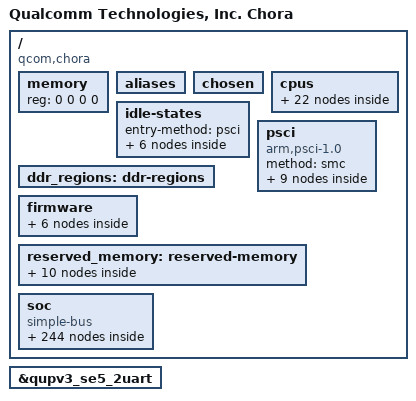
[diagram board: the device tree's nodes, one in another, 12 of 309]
// SPDX-License-Identifier: BSD-3-Clause
/*
 * Copyright (c) Qualcomm Technologies, Inc. and/or its subsidiaries.
 */

#include <dt-bindings/arm/msm/qti-smmu-proxy-dt-ids.h>
#include <dt-bindings/clock/qcom,chora-camcc.h>
#include <dt-bindings/clock/qcom,chora-dispcc.h>
#include <dt-bindings/clock/qcom,chora-gcc.h>
#include <dt-bindings/clock/qcom,chora-gpucc.h>
#include <dt-bindings/clock/qcom,chora-tcsrcc.h>
#include <dt-bindings/clock/qcom,chora-videocc.h>
#include <dt-bindings/clock/qcom,rpmh.h>
#include <dt-bindings/interrupt-controller/arm-gic.h>
#include <dt-bindings/soc/qcom,ipcc.h>
#include <dt-bindings/mailbox/qcom-ipcc-chora.h>
#include <dt-bindings/gpio/gpio.h>
#include <dt-bindings/soc/qcom,rpmh-rsc.h>
#include <dt-bindings/regulator/qcom,rpmh-regulator-levels.h>
#include <dt-bindings/interconnect/qcom,icc.h>
#include <dt-bindings/interconnect/qcom,chora.h>
#include <dt-bindings/spmi/spmi.h>
#include <dt-bindings/dma/qcom-gpi.h>

/ {
	model = "Qualcomm Technologies, Inc. Chora";
	compatible = "qcom,chora";
	qcom,msm-id = <724 0x10000>;
	interrupt-parent = <&intc>;

	#address-cells = <2>;
	#size-cells = <2>;
	memory { device_type = "memory"; reg = <0 0 0 0>; };

	aliases: aliases {
		serial0 = &qupv3_se5_2uart;
		ufshc1 = &ufshc_mem; /* Embedded UFS Slot */
		mmc1 = &sdhc_2; /* SDC2 SD card slot */
		hsuart0 = &qupv3_se11_4uart;
		i2c0 = &qupv3_se0_i2c;
		i2c1 = &qupv3_se1_i2c;
		i2c2 = &qupv3_se2_i2c;
		i2c3 = &qupv3_se3_i2c;
		i2c4 = &qupv3_se4_i2c;
		i2c6 = &qupv3_se6_i2c;
		i2c7 = &qupv3_se7_i2c;
		i2c8 = &qupv3_se8_i2c;
		i2c9 = &qupv3_se9_i2c;
		i2c10 = &qupv3_se10_i2c;
		i2c12 = &qupv3_se12_i2c;
		i2c13 = &qupv3_se13_i2c;
		spi0 = &qupv3_se0_spi;
		spi1 = &qupv3_se1_spi;
		spi2 = &qupv3_se2_spi;
		spi3 = &qupv3_se3_spi;
		spi4 = &qupv3_se4_spi;
		spi6 = &qupv3_se6_spi;
		spi7 = &qupv3_se7_spi;
		spi8 = &qupv3_se8_spi;
		spi10 = &qupv3_se10_spi;
		spi12 = &qupv3_se12_spi;
		spi13 = &qupv3_se13_spi;
	};

	chosen: chosen {
		bootargs = "loglevel=6 log_buf_len=512K earlycon androidboot.usb.dwc3_msm=a600000.hsusb arm64.nosme arm64.nomte cpufreq.default_governor=performance no-steal-acc kpti=0 swiotlb=0 loop.max_part=7 irqaffinity=0-3 fw_devlink.strict=1 kasan=off ufshcd-core.use_mcq_mode=n rcupdate.rcu_expedited=1 rcu_nocbs=0-7 cgroup_disable=pressure cgroup.memory=nokmem,nosocket disable_dma32=on page_poison=on sysctl.kernel.sched_pelt_multiplier=4 android_arch_task_struct_size=512 printk.console_no_auto_verbose=1 sysctl.kernel.panic_on_rcu_stall=1 ftrace_dump_on_oops restrict_cma_redirect=false can.stats_timer=0 slub_debug=-";
		stdout-path = "serial0:115200n8";
	};

	cpus {
		#address-cells = <2>;
		#size-cells = <0>;

		CPU0: cpu@0 {
			device_type = "cpu";
			compatible = "qcom,kryo";
			reg = <0x0 0x0>;
			enable-method = "psci";
			cpu-idle-states = <&LITTLE_CPU_OFF &LITTLE_CPU_RAIL_OFF>;
			power-domains = <&CPU_PD0>;
			power-domain-names = "psci";
			next-level-cache = <&L2_0>;
			capacity-dmips-mhz = <1024>;
			dynamic-power-coefficient = <100>;
			#cooling-cells = <2>;
			qcom,freq-domain = <&cpufreq_hw 0>;

			L2_0: l2-cache {
				compatible = "arm,arch-cache";
				cache-level = <2>;
				next-level-cache = <&L3_0>;

				L3_0: l3-cache {
					compatible = "arm,arch-cache";
					cache-level = <3>;
				};
			};
		};

		CPU1: cpu@100 {
			device_type = "cpu";
			compatible = "qcom,kryo";
			reg = <0x0 0x100>;
			enable-method = "psci";
			cpu-idle-states = <&LITTLE_CPU_OFF &LITTLE_CPU_RAIL_OFF>;
			power-domains = <&CPU_PD1>;
			power-domain-names = "psci";
			next-level-cache = <&L2_0>;
			capacity-dmips-mhz = <1024>;
			dynamic-power-coefficient = <100>;
			#cooling-cells = <2>;
			qcom,freq-domain = <&cpufreq_hw 0>;
		};

		CPU2: cpu@200 {
			device_type = "cpu";
			compatible = "qcom,kryo";
			reg = <0x0 0x200>;
			enable-method = "psci";
			cpu-idle-states = <&LITTLE_CPU_OFF &LITTLE_CPU_RAIL_OFF>;
			power-domains = <&CPU_PD2>;
			power-domain-names = "psci";
			next-level-cache = <&L2_0>;
			capacity-dmips-mhz = <1024>;
			dynamic-power-coefficient = <100>;
			#cooling-cells = <2>;
			qcom,freq-domain = <&cpufreq_hw 0>;
		};

		CPU3: cpu@300 {
			device_type = "cpu";
			compatible = "qcom,kryo";
			reg = <0x0 0x300>;
			enable-method = "psci";
			cpu-idle-states = <&LITTLE_CPU_OFF &LITTLE_CPU_RAIL_OFF>;
			power-domains = <&CPU_PD3>;
			power-domain-names = "psci";
			next-level-cache = <&L2_0>;
			capacity-dmips-mhz = <1024>;
			dynamic-power-coefficient = <100>;
			#cooling-cells = <2>;
			qcom,freq-domain = <&cpufreq_hw 0>;
		};

		CPU4: cpu@400 {
			device_type = "cpu";
			compatible = "qcom,kryo";
			reg = <0x0 0x400>;
			enable-method = "psci";
			cpu-idle-states = <&BIG_CPU_OFF &BIG_CPU_RAIL_OFF>;
			power-domains = <&CPU_PD4>;
			power-domain-names = "psci";
			next-level-cache = <&L2_4>;
			capacity-dmips-mhz = <1864>;
			dynamic-power-coefficient = <471>;
			#cooling-cells = <2>;
			qcom,freq-domain = <&cpufreq_hw 1>;

			L2_4: l2-cache {
				compatible = "arm,arch-cache";
				cache-level = <2>;
				next-level-cache = <&L3_0>;
			};
		};

		CPU5: cpu@500 {
			device_type = "cpu";
			compatible = "qcom,kryo";
			reg = <0x0 0x500>;
			enable-method = "psci";
			cpu-idle-states = <&BIG_CPU_OFF &BIG_CPU_RAIL_OFF>;
			power-domains = <&CPU_PD5>;
			power-domain-names = "psci";
			next-level-cache = <&L2_4>;
			capacity-dmips-mhz = <1864>;
			dynamic-power-coefficient = <471>;
			#cooling-cells = <2>;
			qcom,freq-domain = <&cpufreq_hw 1>;
		};

		CPU6: cpu@600 {
			device_type = "cpu";
			compatible = "qcom,kryo";
			reg = <0x0 0x600>;
			enable-method = "psci";
			cpu-idle-states = <&BIG_CPU_OFF &BIG_CPU_RAIL_OFF>;
			power-domains = <&CPU_PD6>;
			power-domain-names = "psci";
			next-level-cache = <&L2_4>;
			capacity-dmips-mhz = <1864>;
			dynamic-power-coefficient = <471>;
			#cooling-cells = <2>;
			qcom,freq-domain = <&cpufreq_hw 1>;
		};

		CPU7: cpu@700 {
			device_type = "cpu";
			compatible = "qcom,kryo";
			reg = <0x0 0x700>;
			enable-method = "psci";
			cpu-idle-states = <&BIG_CPU_OFF &BIG_CPU_RAIL_OFF>;
			power-domains = <&CPU_PD7>;
			power-domain-names = "psci";
			next-level-cache = <&L2_4>;
			capacity-dmips-mhz = <1864>;
			dynamic-power-coefficient = <471>;
			#cooling-cells = <2>;
			qcom,freq-domain = <&cpufreq_hw 1>;
		};

		cpu-map {

			cluster0 {

				core0 {
					cpu = <&CPU0>;
				};

				core1 {
					cpu = <&CPU1>;
				};

				core2 {
					cpu = <&CPU2>;
				};

				core3 {
					cpu = <&CPU3>;
				};
			};

			cluster1 {

				core0 {
					cpu = <&CPU4>;
				};

				core1 {
					cpu = <&CPU5>;
				};

				core2 {
					cpu = <&CPU6>;
				};

				core3 {
					cpu = <&CPU7>;
				};
			};
		};
	};

	idle-states {
		entry-method = "psci";

		LITTLE_CPU_OFF: silver-c3 {  /* C3 */
			compatible = "arm,idle-state";
			idle-state-name = "pc";
			entry-latency-us = <203>;
			exit-latency-us = <358>;
			min-residency-us = <1774>;
			arm,psci-suspend-param = <0x40000003>;
			local-timer-stop;
		};

		LITTLE_CPU_RAIL_OFF: silver-c4 {  /* C4 */
			compatible = "arm,idle-state";
			idle-state-name = "rail-pc";
			entry-latency-us = <222>;
			exit-latency-us = <391>;
			min-residency-us = <4090>;
			arm,psci-suspend-param = <0x40000004>;
			local-timer-stop;
		};

		BIG_CPU_OFF: gold-c3 {  /* C3 */
			compatible = "arm,idle-state";
			idle-state-name = "pc";
			entry-latency-us = <330>;
			exit-latency-us = <890>;
			min-residency-us = <2207>;
			arm,psci-suspend-param = <0x40000003>;
			local-timer-stop;
		};

		BIG_CPU_RAIL_OFF: gold-c4 {  /* C4 */
			compatible = "arm,idle-state";
			idle-state-name = "rail-pc";
			entry-latency-us = <354>;
			exit-latency-us = <1344>;
			min-residency-us = <4791>;
			arm,psci-suspend-param = <0x40000004>;
			local-timer-stop;
		};

		CLUSTER_OFF: cluster-d4 { /* D4 */
			compatible = "domain-idle-state";
			idle-state-name = "l3-off";
			entry-latency-us = <690>;
			exit-latency-us = <1843>;
			min-residency-us = <5309>;
			arm,psci-suspend-param = <0x41000044>;
		};

		CX_RET: cx-ret { /* Cx Ret */
			compatible = "domain-idle-state";
			idle-state-name = "cx-ret";
			entry-latency-us = <528>;
			exit-latency-us = <2237>;
			min-residency-us = <8550>;
			arm,psci-suspend-param = <0x41003344>;
		};
	};

	psci: psci {
		compatible = "arm,psci-1.0";
		method = "smc";

		CPU_PD0: cpu-pd0 {
			#power-domain-cells = <0>;
			power-domains = <&CLUSTER_PD>;
		};

		CPU_PD1: cpu-pd1 {
			#power-domain-cells = <0>;
			power-domains = <&CLUSTER_PD>;
		};

		CPU_PD2: cpu-pd2 {
			#power-domain-cells = <0>;
			power-domains = <&CLUSTER_PD>;
		};

		CPU_PD3: cpu-pd3 {
			#power-domain-cells = <0>;
			power-domains = <&CLUSTER_PD>;
		};

		CPU_PD4: cpu-pd4 {
			#power-domain-cells = <0>;
			power-domains = <&CLUSTER_PD>;
		};

		CPU_PD5: cpu-pd5 {
			#power-domain-cells = <0>;
			power-domains = <&CLUSTER_PD>;
		};

		CPU_PD6: cpu-pd6 {
			#power-domain-cells = <0>;
			power-domains = <&CLUSTER_PD>;
		};

		CPU_PD7: cpu-pd7 {
			#power-domain-cells = <0>;
			power-domains = <&CLUSTER_PD>;
		};

		CLUSTER_PD: cluster-pd {
			#power-domain-cells = <0>;
			domain-idle-states = <&CLUSTER_OFF &CX_RET>;
		};
	};

	ddr_regions: ddr-regions { };

	firmware: firmware { };

	reserved_memory: reserved-memory { };

	soc: soc { };
};

&firmware {
	qcom_scm: qcom_scm {
		compatible = "qcom,scm";
		qcom,dload-mode = <&tcsr 0x19000>;
	};

	qcom,sps {
		compatible = "qcom,msm-sps-v1_7-4k";
		qcom,pipe-attr-ee;
	};

	qcom_smcinvoke {
		compatible = "qcom,smcinvoke";
	};

	qcom_mem_object {
		compatible = "qcom,mem-object";
	};

	qtee_shmbridge {
		compatible = "qcom,tee-shared-memory-bridge";
	};

	qcom,hdcp {
		compatible = "qcom,hdcp";
		qcom,use-smcinvoke = <1>;
	};

};

#include "chora-reserved-memory.dtsi"
#include "msm-arm-smmu-chora.dtsi"
#include "chora-dma-heaps.dtsi"

&reserved_memory {
	#address-cells = <2>;
	#size-cells = <2>;
	ranges;

	adsp_mem_heap: adsp_heap_region {
		compatible = "shared-dma-pool";
		alloc-ranges = <0x0 0x00000000 0x0 0xffffffff>;
		reusable;
		alignment = <0x0 0x400000>;
		size = <0x0 0xC00000>;
	};

	non_secure_display_memory: non_secure_display_region {
		compatible = "shared-dma-pool";
		reusable;
		alloc-ranges = <0x0 0x00000000 0x0 0xffffffff>;
		size = <0x0 0x5c00000>;
		alignment = <0x0 0x400000>;
	};

	/* global autoconfigured region for contiguous allocations */
	system_cma: linux,cma {
		compatible = "shared-dma-pool";
		alloc-ranges = <0x0 0x00000000 0x0 0xffffffff>;
		reusable;
		alignment = <0x0 0x400000>;
		size = <0x0 0x2400000>;
		linux,cma-default;
	};

	lcp_dare_pool: lcp_dare_region {
		compatible = "shared-dma-pool";
		reg = <0x8 0x80000000 0x0 0x6000000>;
		reusable;
		alignment = <0x0 0x400000>;
	};

	kinfo_mem: debug_kinfo_region {
		alloc-ranges = <0x0 0x00000000 0xffffffff 0xffffffff>;
		size = <0x0 0x1000>;
		no-map;
	};

	ramoops_mem: ramoops-region {
		alloc-ranges = <0x1 0x00000000 0xfffffffe 0xffffffff>;
		size = <0x0 0x200000>;
		no-map;
	};

	va_md_mem: va_md_mem_region {
		compatible = "shared-dma-pool";
		alloc-ranges = <0x0 0x00000000 0x0 0xffffffff>;
		reusable;
		size = <0 0x1000000>;
	};

	qseecom_mem: qseecom_region {
		compatible = "shared-dma-pool";
		alloc-ranges = <0x0 0x00000000 0x0 0xffffffff>;
		reusable;
		alignment = <0x0 0x400000>;
		size = <0x0 0x1400000>;
	};

	qseecom_ta_mem: qseecom_ta_region {
		compatible = "shared-dma-pool";
		alloc-ranges = <0x0 0x00000000 0x0 0xffffffff>;
		reusable;
		alignment = <0x0 0x400000>;
		size = <0x0 0x1400000>;
	};

	vm_comm_mem: vm_comm_mem_region {
		compatible = "shared-dma-pool";
		alloc-ranges = <0x0 0x00000000 0x0 0xffffffff>;
		reusable;
		alignment = <0x0 0x400000>;
		size = <0x0 0x800000>;
	};
};

&soc {
	#address-cells = <2>;
	#size-cells = <2>;
	ranges = <0 0 0 0 0x10 0>;
	compatible = "simple-bus";

	qcom,secure-buffer {
		compatible = "qcom,secure-buffer";
		qcom,vmid-cp-camera-preview-ro;
	};

	qcom,mem-buf {
		compatible = "qcom,mem-buf";
		qcom,mem-buf-capabilities = "supplier";
		qcom,vmid = <3>;
	};

	qcom,mem-buf-msgq {
		compatible = "qcom,mem-buf-msgq";
		qcom,msgq-names = "trusted_vm", "oem_vm";
	};

	qcom,test-large-dmabuf-tuivm {
		compatible = "qcom,gh-large-dmabuf-test";
		gunyah-label = <0x10d>;
		qcom,primary;
	};

	qcom,test-large-dmabuf-oemvm {
		compatible = "qcom,gh-large-dmabuf-test";
		gunyah-label = <0x10e>;
		qcom,primary;
	};

	msm_gpu: qcom,kgsl-3d0@3d00000 { };

	thermal_zones: thermal-zones {};

	intc: interrupt-controller@17200000 {
		compatible = "arm,gic-v3";
		#interrupt-cells = <3>;
		interrupt-controller;
		#redistributor-regions = <1>;
		redistributor-stride = <0x0 0x20000>;
		reg = <0x0 0x17200000 0x0 0x10000>,	/* GICD */
		      <0x0 0x17260000 0x0 0x100000>;	/* GICR * 8 */
		interrupts = <GIC_PPI 9 IRQ_TYPE_LEVEL_LOW>;

		#address-cells = <1>;
		#size-cells = <1>;
		ranges;
		gic_its: msi-controller@17240000 {
			compatible = "arm,gic-v3-its";
			msi-controller;
			#msi-cells = <1>;
			reg = <0x17240000 0x20000>;
		};
	};

	arch_timer: timer {
		compatible = "arm,armv8-timer";
		interrupts = <GIC_PPI 13 (GIC_CPU_MASK_SIMPLE(8) | IRQ_TYPE_LEVEL_LOW)>,
			     <GIC_PPI 14 (GIC_CPU_MASK_SIMPLE(8) | IRQ_TYPE_LEVEL_LOW)>,
			     <GIC_PPI 11 (GIC_CPU_MASK_SIMPLE(8) | IRQ_TYPE_LEVEL_LOW)>,
			     <GIC_PPI 10 (GIC_CPU_MASK_SIMPLE(8) | IRQ_TYPE_LEVEL_LOW)>;
		clock-frequency = <19200000>;
	};

	memtimer: timer@17420000 {
		compatible = "arm,armv7-timer-mem";
		reg = <0x0 0x17420000 0x0 0x1000>;
		clock-frequency = <19200000>;

		#address-cells = <1>;
		#size-cells = <1>;
		ranges;
		frame@17421000 {
			frame-number = <0>;
			interrupts = <GIC_SPI 8 IRQ_TYPE_LEVEL_HIGH>,
				     <GIC_SPI 6 IRQ_TYPE_LEVEL_HIGH>;
			reg = <0x17421000 0x1000>,
			      <0x17422000 0x1000>;
		};

		frame@17423000 {
			frame-number = <1>;
			interrupts = <GIC_SPI 9 IRQ_TYPE_LEVEL_HIGH>;
			reg = <0x17423000 0x1000>;
			status = "disabled";
		};

		frame@17425000 {
			frame-number = <2>;
			interrupts = <GIC_SPI 10 IRQ_TYPE_LEVEL_HIGH>;
			reg = <0x17425000 0x1000>;
			status = "disabled";
		};

		frame@17427000 {
			frame-number = <3>;
			interrupts = <GIC_SPI 11 IRQ_TYPE_LEVEL_HIGH>;
			reg = <0x17427000 0x1000>;
			status = "disabled";
		};

		frame@17429000 {
			frame-number = <4>;
			interrupts = <GIC_SPI 12 IRQ_TYPE_LEVEL_HIGH>;
			reg = <0x17429000 0x1000>;
			status = "disabled";
		};

		frame@1742b000 {
			frame-number = <5>;
			interrupts = <GIC_SPI 13 IRQ_TYPE_LEVEL_HIGH>;
			reg = <0x1742b000 0x1000>;
			status = "disabled";
		};

		frame@1742d000 {
			frame-number = <6>;
			interrupts = <GIC_SPI 14 IRQ_TYPE_LEVEL_HIGH>;
			reg = <0x1742d000 0x1000>;
			status = "disabled";
		};
	};

	apps_rsc: rsc@17a00000 {
		label = "apps_rsc";
		compatible = "qcom,rpmh-rsc";
		reg = <0x0 0x17a00000 0x0 0x10000>,
		      <0x0 0x17a10000 0x0 0x10000>,
		      <0x0 0x17a20000 0x0 0x10000>;
		reg-names = "drv-0", "drv-1", "drv-2";
		qcom,drv-count = <3>;
		interrupts = <GIC_SPI 3 IRQ_TYPE_LEVEL_HIGH>,
			     <GIC_SPI 4 IRQ_TYPE_LEVEL_HIGH>,
			     <GIC_SPI 5 IRQ_TYPE_LEVEL_HIGH>;
		power-domains = <&CLUSTER_PD>;

		apps_rsc_drv2: drv@2 {
			qcom,drv-id = <2>;
			qcom,tcs-offset = <0xd00>;
			qcom,tcs-distance = <0x2a0>;

			channel@0 {
				 qcom,tcs-config = <ACTIVE_TCS    3>,
						   <SLEEP_TCS     2>,
						   <WAKE_TCS      2>,
						   <CONTROL_TCS   0>,
						   <FAST_PATH_TCS 1>;
			};

			apps_bcm_voter: bcm_voter {
				compatible = "qcom,bcm-voter";
			};

			rpmhcc: clock-controller {
				compatible = "qcom,chora-rpmh-clk";
				#clock-cells = <1>;
			};

			dcvs_fp: qcom,dcvs-fp {
				compatible = "qcom,dcvs-fp";
				qcom,ddr-bcm-name = "MC4";
			};
		};
	};

	pdc: interrupt-controller@0xb220000 {
		compatible = "qcom,chora-pdc", "qcom,pdc";
		reg = <0x0 0xb220000 0x0 0x10000>,
		      <0x0 0x174000f0 0x0 0x64>;
		qcom,pdc-ranges = <0 480 40>, <40 140 11>, <51 527 47>,
				  <98 609 31>, <129 63 1>, <130 716 12>,
				  <142 251 5>;
		#interrupt-cells = <2>;
		interrupt-parent = <&intc>;
		interrupt-controller;
	};

	disp_rsc: rsc@af20000 {
		label = "disp_rsc";
		compatible = "qcom,rpmh-rsc";
		reg = <0x0 0xaf20000 0x0 0x10000>;
		reg-names = "drv-0";
		qcom,drv-count = <1>;
		interrupts = <GIC_SPI 129 IRQ_TYPE_LEVEL_HIGH>;
		clocks = <&dispcc DISP_CC_MDSS_RSCC_AHB_CLK>;

		disp_rsc_drv0: drv@0 {
			qcom,tcs-offset = <0x1c00>;
			qcom,drv-id = <0>;
			channel@0 {
				qcom,tcs-config = <ACTIVE_TCS    0>,
						  <SLEEP_TCS     1>,
						  <WAKE_TCS      1>,
						  <CONTROL_TCS   0>,
						  <FAST_PATH_TCS 0>;
			};

			disp_bcm_voter: bcm_voter {
				compatible = "qcom,bcm-voter";
				qcom,tcs-wait = <QCOM_ICC_TAG_AMC>;
			};
		};
	};

	cluster-device {
		compatible = "qcom,lpm-cluster-dev";
		power-domains = <&CLUSTER_PD>;
	};

	gic-interrupt-router {
		compatible = "qcom,gic-intr-routing";
		/* keep few silver cores in class0 only to avoid wakeup of gold cores */
		qcom,gic-class0-cpus = <&CPU0 &CPU1 &CPU2 &CPU3>;
		/* keep gold cores in class1 */
		qcom,gic-class1-cpus = <&CPU4 &CPU5 &CPU6 &CPU7>;
		qcom,gic-cpulist = <&CPU0 &CPU1 &CPU2 &CPU3 &CPU4 &CPU5 &CPU6 &CPU7>;
		qcom,gic-runtime-cpu-class-en;
	};

	wdog: qcom,wdt@17410000 {
		compatible = "qcom,msm-watchdog";
		reg = <0x0 0x17410000 0x0 0x1000>;
		reg-names = "wdt-base";
		interrupts = <GIC_SPI 0 IRQ_TYPE_LEVEL_HIGH>,
			     <GIC_SPI 1 IRQ_TYPE_LEVEL_HIGH>;
		qcom,bark-time = <11000>;
		qcom,pet-time = <9360>;
		qcom,ipi-ping;
		qcom,wakeup-enable;

		status = "ok";
	};

	kryo-erp {
		compatible = "arm,arm64-kryo-cpu-erp";
		interrupts = <GIC_PPI 0 IRQ_TYPE_LEVEL_HIGH>,
			<GIC_SPI 35 IRQ_TYPE_LEVEL_HIGH>;
		interrupt-names = "l1-l2-faultirq","l3-scu-faultirq";
	};

	qcom,chd {
		compatible = "qcom,core-hang-detect";
		label = "core";
		qcom,chd-percpu-info = <&CPU0 0x17800058 0x17800060>,
			<&CPU1 0x17810058 0x17810060>,
			<&CPU2 0x17820058 0x17820060>,
			<&CPU3 0x17830058 0x17830060>,
			<&CPU4 0x17840058 0x17840060>,
			<&CPU5 0x17850058 0x17850060>,
			<&CPU6 0x17860058 0x17860060>,
			<&CPU7 0x17870058 0x17870060>;
	};

	ipcc_mproc: qcom,ipcc@404000 {
		compatible = "qcom,ipcc";
		reg = <0x0 0x404000 0x0 0x1000>;
		interrupts = <GIC_SPI 256 IRQ_TYPE_LEVEL_HIGH>;
		interrupt-controller;
		#interrupt-cells = <3>;
		#mbox-cells = <2>;
	};

	spmi_bus: spmi0_bus: qcom,spmi@c42d000 {
		compatible = "qcom,spmi-pmic-arb";
		reg = <0x0 0xc42d000 0x0 0x4000>,
		      <0x0 0xc400000 0x0 0x3000>,
		      <0x0 0xc500000 0x0 0x400000>,
		      <0x0 0xc440000 0x0 0x80000>,
		      <0x0 0xc4c0000 0x0 0x10000>;
		reg-names = "cnfg", "core", "chnls", "obsrvr", "intr";
		interrupts-extended = <&pdc 1 IRQ_TYPE_LEVEL_HIGH>;
		interrupt-names = "periph_irq";
		interrupt-controller;
		#interrupt-cells = <4>;
		#address-cells = <2>;
		#size-cells = <0>;
		cell-index = <0>;
		qcom,channel = <0>;
		qcom,ee = <0>;
		qcom,bus-id = <0>;
	};

	aoss_qmp: power-controller@c300000 {
		compatible = "qcom,aoss-qmp";
		reg = <0x0 0xc300000 0x0 0x400>;
		interrupt-parent = <&ipcc_mproc>;
		interrupts = <IPCC_CLIENT_AOP
			      IPCC_MPROC_SIGNAL_GLINK_QMP
			      IRQ_TYPE_EDGE_RISING>;
		mboxes = <&ipcc_mproc IPCC_CLIENT_AOP
			  IPCC_MPROC_SIGNAL_GLINK_QMP>;

		#power-domain-cells = <1>;
		#clock-cells = <0>;
	};

	spmi_debug_bus_0: qcom,spmi-debug@10b14000 {
		compatible = "qcom,spmi-pmic-arb-debug";
		reg = <0x0 0x10b14000 0x0 0x60>,
		      <0x0 0x221c8780 0x0 0x4>;
		reg-names = "core", "fuse";
		clocks = <&aoss_qmp>;
		clock-names = "core_clk";
		qcom,fuse-enable-bit = <14>;
		#address-cells = <1>;
		#size-cells = <0>;
		depends-on-supply = <&spmi0_bus>;

		pmk8550@0 {
			compatible = "qcom,spmi-pmic";
			reg = <0 SPMI_USID>;
			#address-cells = <2>;
			#size-cells = <0>;
			qcom,can-sleep;
		};

		pmxr2230@1 {
			compatible = "qcom,spmi-pmic";
			reg = <1 SPMI_USID>;
			#address-cells = <2>;
			#size-cells = <0>;
			qcom,can-sleep;
		};

		pm8550vs@2 {
			compatible = "qcom,spmi-pmic";
			reg = <2 SPMI_USID>;
			#address-cells = <2>;
			#size-cells = <0>;
			qcom,can-sleep;
		};

		pmr735b@5 {
			compatible = "qcom,spmi-pmic";
			reg = <5 SPMI_USID>;
			#address-cells = <2>;
			#size-cells = <0>;
			qcom,can-sleep;
		};

		pm8010@c {
			compatible = "qcom,spmi-pmic";
			reg = <12 SPMI_USID>;
			#address-cells = <2>;
			#size-cells = <0>;
			qcom,can-sleep;
		};

		pm8010@d {
			compatible = "qcom,spmi-pmic";
			reg = <13 SPMI_USID>;
			#address-cells = <2>;
			#size-cells = <0>;
			qcom,can-sleep;
		};
	};

	qmp_tme: qcom,qmp-tme {
		compatible = "qcom,qmp-mbox";
		qcom,remote-pid = <14>;
		mboxes = <&ipcc_mproc IPCC_CLIENT_TME
			  IPCC_MPROC_SIGNAL_GLINK_QMP>;
		mbox-names = "tme_qmp";
		interrupt-parent = <&ipcc_mproc>;
		interrupts = <IPCC_CLIENT_TME
			      IPCC_MPROC_SIGNAL_GLINK_QMP
			      IRQ_TYPE_EDGE_RISING>;

		label = "tme";
		qcom,early-boot;
		priority = <0>;
		mbox-desc-offset = <0x0>;
		#mbox-cells = <1>;
	};

	qcom,smp2p-adsp {
		compatible = "qcom,smp2p";
		qcom,smem = <443>, <429>;
		interrupt-parent = <&ipcc_mproc>;
		interrupts = <IPCC_CLIENT_LPASS IPCC_MPROC_SIGNAL_SMP2P
			      IRQ_TYPE_EDGE_RISING>;
		mboxes = <&ipcc_mproc IPCC_CLIENT_LPASS
			  IPCC_MPROC_SIGNAL_SMP2P>;
		qcom,local-pid = <0>;
		qcom,remote-pid = <2>;

		adsp_smp2p_out: master-kernel {
			qcom,entry-name = "master-kernel";
			#qcom,smem-state-cells = <1>;
		};

		adsp_smp2p_in: slave-kernel {
			qcom,entry-name = "slave-kernel";
			interrupt-controller;
			#interrupt-cells = <2>;
		};

		sleepstate_smp2p_out: sleepstate-out {
			qcom,entry-name = "sleepstate";
			#qcom,smem-state-cells = <1>;
		};

		sleepstate_smp2p_in: qcom,sleepstate-in {
			qcom,entry-name = "sleepstate_see";
			interrupt-controller;
			#interrupt-cells = <2>;
		};

		smp2p_rdbg2_out: qcom,smp2p-rdbg2-out {
			qcom,entry-name = "rdbg";
			#qcom,smem-state-cells = <1>;
		};

		smp2p_rdbg2_in: qcom,smp2p-rdbg2-in {
			qcom,entry-name = "rdbg";
			interrupt-controller;
			#interrupt-cells = <2>;
		};
	};

	qcom,smp2p-modem {
		compatible = "qcom,smp2p";
		qcom,smem = <435>, <428>;
		interrupt-parent = <&ipcc_mproc>;
		interrupts = <IPCC_CLIENT_MPSS IPCC_MPROC_SIGNAL_SMP2P
			      IRQ_TYPE_EDGE_RISING>;
		mboxes = <&ipcc_mproc IPCC_CLIENT_MPSS IPCC_MPROC_SIGNAL_SMP2P>;
		qcom,local-pid = <0>;
		qcom,remote-pid = <1>;

		modem_smp2p_out: master-kernel {
			qcom,entry-name = "master-kernel";
			#qcom,smem-state-cells = <1>;
		};

		modem_smp2p_in: slave-kernel {
			qcom,entry-name = "slave-kernel";
			interrupt-controller;
			#interrupt-cells = <2>;
		};

		smp2p_ipa_1_out: qcom,smp2p-ipa-1-out {
			qcom,entry-name = "ipa";
			#qcom,smem-state-cells = <1>;
		};

		/* ipa - inbound entry from mss */
		smp2p_ipa_1_in: qcom,smp2p-ipa-1-in {
			qcom,entry-name = "ipa";
			interrupt-controller;
			#interrupt-cells = <2>;
		};

		smp2p_smem_mailbox_1_out: qcom,smp2p-smem-mailbox-1-out {
			qcom,entry-name = "smem-mailbox";
			#qcom,smem-state-cells = <1>;
		};

		smp2p_smem_mailbox_1_in: qcom,smp2p-smem-mailbox-1-in {
			qcom,entry-name = "smem-mailbox";
			interrupt-controller;
			#interrupt-cells = <2>;
		};
	};

	qcom,smp2p-wpss {
		compatible = "qcom,smp2p";
		qcom,smem = <617>, <616>;
		interrupt-parent = <&ipcc_mproc>;
		interrupts = <IPCC_CLIENT_WPSS IPCC_MPROC_SIGNAL_SMP2P
			      IRQ_TYPE_EDGE_RISING>;
		mboxes = <&ipcc_mproc IPCC_CLIENT_WPSS IPCC_MPROC_SIGNAL_SMP2P>;
		qcom,local-pid = <0>;
		qcom,remote-pid = <13>;

		wpss_smp2p_out: master-kernel {
			qcom,entry-name = "master-kernel";
			#qcom,smem-state-cells = <1>;
		};

		wpss_smp2p_in: slave-kernel {
			qcom,entry-name = "slave-kernel";
			interrupt-controller;
			#interrupt-cells = <2>;
		};
	};

	qcom,smp2p_sleepstate {
		compatible = "qcom,smp2p-sleepstate";
		qcom,smem-states = <&sleepstate_smp2p_out 0>;
		interrupt-parent = <&sleepstate_smp2p_in>;
		interrupts = <0 0>;
		interrupt-names = "smp2p-sleepstate-in";
	};

	qcom,qrtr-gunyah-oemvm {
		compatible = "qcom,qrtr-gunyah";
		qcom,master;
		gunyah-label = <0x108>;
		peer-name = <4>;
	};

	pmic-glink {
		compatible = "qcom,qti-pmic-glink";
		qcom,pmic-glink-channel = "PMIC_RTR_ADSP_APPS";
		depends-on-supply = <&ipcc_mproc>;
		qcom,subsys-name = "lpass";
		qcom,protection-domain = "tms/servreg", "msm/adsp/charger_pd";

		battery_charger: battery-charger {
			compatible = "qcom,battery-charger";
		};

		ucsi: ucsi-glink {
			compatible = "qcom,ucsi-glink";

		};

		altmode: altmode-glink {
			compatible = "qcom,altmode-glink";
			#altmode-cells = <1>;
		};
	};

	pmic-glink-log {
		compatible = "qcom,qti-pmic-glink";
		qcom,pmic-glink-channel = "PMIC_LOGS_ADSP_APPS";

		battery-debug {
			compatible = "qcom,battery-debug";
		};

		charger-ulog-glink {
			compatible = "qcom,charger-ulog-glink";
		};

		pmic_glink_debug: pmic-glink-debug {
			compatible = "qcom,pmic-glink-debug";
			#address-cells = <1>;
			#size-cells = <0>;
			depends-on-supply = <&spmi0_bus>;
		};

		pmic_glink_adc: glink-adc {
			compatible = "qcom,glink-adc";
			#address-cells = <1>;
			#size-cells = <0>;
			#io-channel-cells = <1>;
			status = "disabled";
		};
	};

	qcom,glinkpkt {
		compatible = "qcom,glinkpkt";

		qcom,glinkpkt-at-mdm0 {
			qcom,glinkpkt-edge = "mpss";
			qcom,glinkpkt-ch-name = "DS";
			qcom,glinkpkt-dev-name = "at_mdm0";
		};

		qcom,glinkpkt-apr-apps2 {
			qcom,glinkpkt-edge = "adsp";
			qcom,glinkpkt-ch-name = "apr_apps2";
			qcom,glinkpkt-dev-name = "apr_apps2";
		};

		qcom,glinkpkt-data40-cntl {
			qcom,glinkpkt-edge = "mpss";
			qcom,glinkpkt-ch-name = "DATA40_CNTL";
			qcom,glinkpkt-dev-name = "smdcntl8";
		};

		qcom,glinkpkt-data1 {
			qcom,glinkpkt-edge = "mpss";
			qcom,glinkpkt-ch-name = "DATA1";
			qcom,glinkpkt-dev-name = "smd7";
		};

		qcom,glinkpkt-data4 {
			qcom,glinkpkt-edge = "mpss";
			qcom,glinkpkt-ch-name = "DATA4";
			qcom,glinkpkt-dev-name = "smd8";
		};

		qcom,glinkpkt-data11 {
			qcom,glinkpkt-edge = "mpss";
			qcom,glinkpkt-ch-name = "DATA11";
			qcom,glinkpkt-dev-name = "smd11";
		};

		qcom,glinkpkt-qmc-dma {
			qcom,glinkpkt-edge = "mpss";
			qcom,glinkpkt-ch-name = "QMC_DMA_LINE";
			qcom,glinkpkt-dev-name = "qmc_dma";
			qcom,glinkpkt-enable-ch-close;
		};

		qcom,glinkpkt-qmc-cma {
			qcom,glinkpkt-edge = "mpss";
			qcom,glinkpkt-ch-name = "QMC_CMA_LINE";
			qcom,glinkpkt-dev-name = "qmc_cma";
			qcom,glinkpkt-enable-ch-close;
		};

		qcom,glinkpkt-ims-sub-1 {
			qcom,glinkpkt-edge = "mpss";
			qcom,glinkpkt-ch-name = "Ims_dc_sub1";
			qcom,glinkpkt-dev-name = "ims_dc_sub1";
			qcom,glinkpkt-enable-ch-close;
		};

		qcom,glinkpkt-ims-sub-2 {
			qcom,glinkpkt-edge = "mpss";
			qcom,glinkpkt-ch-name = "Ims_dc_sub2";
			qcom,glinkpkt-dev-name = "ims_dc_sub2";
			qcom,glinkpkt-enable-ch-close;
		};

		qcom,glinkpkt-xpan_control {
			qcom,glinkpkt-edge = "adsp";
			qcom,glinkpkt-ch-name = "bt_cp_ctrl";
			qcom,glinkpkt-dev-name = "bt_cp_ctrl";
		};
	};

	qcom,glink {
		compatible = "qcom,glink";
	};

	tlmm: pinctrl@f000000 {
		compatible = "qcom,chora-tlmm";
		reg = <0x0 0xf000000 0x0 0x1000000>;
		gpio-controller;
		#gpio-cells = <2>;
		interrupt-controller;
		#interrupt-cells = <2>;
		interrupts = <GIC_SPI 208 IRQ_TYPE_LEVEL_HIGH>;
		qcom,gpios-reserved = <27 28 29 30 57 58 63>;
		wakeup-parent = <&pdc>;
	};

	tcsr_mutex_block: syscon@1f40000 {
		compatible = "syscon";
		reg = <0x0 0x1f40000 0x0 0x20000>;
	};

	tcsr_mutex: hwlock {
		compatible = "qcom,tcsr-mutex";
		syscon = <&tcsr_mutex_block 0 0x1000>;
		#hwlock-cells = <1>;
	};

	tcsr: syscon@1fc0000 {
		compatible = "syscon";
		reg = <0x0 0x1fc0000 0x0 0x30000>;
	};

	eud: qcom,msm-eud@88e0000 {
		compatible = "qcom,msm-eud";
		interrupt-names = "eud_irq";
		interrupt-parent = <&pdc>;
		interrupts = <11 IRQ_TYPE_LEVEL_HIGH>;
		reg = <0x0 0x88e0000 0x0 0x2000>,
			<0x0 0x88e2000 0x0 0x1000>;
		reg-names = "eud_base", "eud_mode_mgr2";
		qcom,secure-eud-en;

		status = "ok";
	};

	cpu_pmu: cpu-pmu {
		compatible = "arm,armv8-pmuv3";
		interrupts = <GIC_PPI 7 IRQ_TYPE_LEVEL_LOW>;
	};

	qcom,mpm2-sleep-counter@c221000 {
		compatible = "qcom,mpm2-sleep-counter";
		reg = <0x0 0xc221000 0x0 0x1000>;
		clock-frequency = <32768>;
	};

	vendor_hooks: qcom,cpu-vendor-hooks {
		compatible = "qcom,cpu-vendor-hooks";
	};

	logbuf: qcom,logbuf-vendor-hooks {
		compatible = "qcom,logbuf-vendor-hooks";
	};

	google,debug-kinfo {
		compatible = "google,debug-kinfo";
		memory-region = <&kinfo_mem>;
	};

	qcom_ramoops {
		compatible = "qcom,ramoops";
		memory-region = <&ramoops_mem>;
		pmsg-size = <0x200000>;
		mem-type = <2>;
	};

	mini_dump_mode {
		compatible = "qcom,minidump";
	};

	va_mini_dump {
		compatible = "qcom,va-minidump";
		memory-region = <&va_md_mem>;
	};

	qcom,msm-imem@14680000 {
		compatible = "qcom,msm-imem";
		reg = <0x0 0x14680000 0x0 0x1000>;
		ranges = <0x0 0x0 0x14680000 0x1000>;
		#address-cells = <1>;
		#size-cells = <1>;

		mem_dump_table@10 {
			compatible = "qcom,msm-imem-mem_dump_table";
			reg = <0x10 0x8>;
		};

		restart_reason@65c {
			compatible = "qcom,msm-imem-restart_reason";
			reg = <0x65c 0x4>;
		};

		dload_type@1c {
			compatible = "qcom,msm-imem-dload-type";
			reg = <0x1c 0x4>;
		};

		boot_stats@6b0 {
			compatible = "qcom,msm-imem-boot_stats";
			reg = <0x6b0 0x20>;
		};

		kaslr_offset@6d0 {
			compatible = "qcom,msm-imem-kaslr_offset";
			reg = <0x6d0 0xc>;
		};

		pil@94c {
			compatible = "qcom,pil-reloc-info";
			reg = <0x94c 0xc8>;
		};

		pil@6dc {
			compatible = "qcom,msm-imem-pil-disable-timeout";
			reg = <0x6dc 0x4>;
		};

		diag_dload@c8 {
			compatible = "qcom,msm-imem-diag-dload";
			reg = <0xc8 0xc8>;
		};

		modem_dsm@c98 {
			compatible = "qcom,msm-imem-mss-dsm";
			reg = <0xc98 0x10>;
		};

		sys_dbg@af8 {
			compatible = "qcom,msm-imem-gpu-dump-skip";
			reg = <0xb0c 0x4>;
		};
	};

	qfprom: qfprom@221c8000 {
		compatible = "qcom,chora-qfprom", "qcom,qfprom";
		reg = <0x0 0x221c8000 0x0 0x1000>;
		#address-cells = <1>;
		#size-cells = <1>;
		read-only;
		ranges;
		feat_conf17: feat_conf17@0144 {
			reg = <0x0144 0x4>;
		};

		gpu_speed_bin: gpu_speed_bin@142 {
			reg = <0x142 0x2>;
			bits = <3 9>;
		};
	};

	qcom,memshare {
		compatible = "qcom,memshare";

		qcom,client_gps {
			compatible = "qcom,memshare-peripheral";
			client_name = "gps";
			qcom,peripheral-size = <0x0>;
			qcom,client-id = <0>;
			qcom,allocate-boot-time;
			label = "modem";
		};

		qcom,client_ftm {
			compatible = "qcom,memshare-peripheral";
			client_name = "ftm";
			qcom,peripheral-size = <0x0>;
			qcom,client-id = <2>;
			label = "modem";
		};

		qcom,client_diag {
			compatible = "qcom,memshare-peripheral";
			client_name = "diag";
			qcom,peripheral-size = <0x500000>;
			qcom,client-id = <1>;
			qcom,allocate-on-request;
			label = "modem";
		};

		qcom,client_ims_1 {
			compatible = "qcom,memshare-peripheral";
			client_name = "ims_1";
			qcom,peripheral-size = <0x100000>;
			qcom,client-id = <7>;
			qcom,allocate-on-request;
			qcom,shared;
			label = "modem";
		};

		qcom,client_ims_2 {
			compatible = "qcom,memshare-peripheral";
			client_name = "ims_2";
			qcom,peripheral-size = <0x100000>;
			qcom,client-id = <8>;
			qcom,allocate-on-request;
			qcom,shared;
			label = "modem";
		};
	};

	cpuss-sleep-stats@17800054 {
		compatible = "qcom,cpuss-sleep-stats-v4";
		reg = <0x0 0x17800054 0x0 0x4>, <0x0 0x17810054 0x0 0x4>,
		      <0x0 0x17820054 0x0 0x4>, <0x0 0x17830054 0x0 0x4>,
		      <0x0 0x17840054 0x0 0x4>, <0x0 0x17850054 0x0 0x4>,
		      <0x0 0x17860054 0x0 0x4>, <0x0 0x17870054 0x0 0x4>,
		      <0x0 0x17880098 0x0 0x4>, <0x0 0x178C0000 0x0 0x10000>;
		reg-names = "seq_lpm_cntr_cfg_cpu0", "seq_lpm_cntr_cfg_cpu1",
			  "seq_lpm_cntr_cfg_cpu2", "seq_lpm_cntr_cfg_cpu3",
			  "seq_lpm_cntr_cfg_cpu4", "seq_lpm_cntr_cfg_cpu5",
			  "seq_lpm_cntr_cfg_cpu6", "seq_lpm_cntr_cfg_cpu7",
			  "l3_seq_lpm_cntr_cfg", "apss_seq_mem_base";
		num-cpus = <8>;
	};

	sram@c3f0000 {
		compatible = "qcom,rpmh-stats-v4";
		reg = <0x0 0xc3f0000 0x0 0x400>;
		ss-name = "modem", "adsp", "adsp_island",
			  "cdsp", "apss", "wpss";
		qcom,qmp = <&aoss_qmp>;
	};

	sys-pm-vx@c320000 {
		compatible = "qcom,sys-pm-violators", "qcom,sys-pm-chora";
		reg = <0x0 0xc320000 0x0 0x0400>;
		qcom,qmp = <&aoss_qmp>;
	};

	qcom_tzlog: tz-log@14680720 {
		compatible = "qcom,tz-log";
		reg = <0x0 0x14680720 0x0 0x3000>;
		qcom,hyplog-enabled;
		hyplog-address-offset = <0x410>;
		hyplog-size-offset = <0x414>;
		tmecrashdump-address-offset = <0x81CA0000>;
	};

	qcom_cedev: qcedev@1de0000 {
		compatible = "qcom,qcedev";
		reg = <0x0 0x1de0000 0x0 0x20000>,
			<0x0 0x1dc4000 0x0 0x28000>;
		reg-names = "crypto-base","crypto-bam-base";
		interrupts = <GIC_SPI 272 IRQ_TYPE_LEVEL_HIGH>,
			<GIC_SPI 274 IRQ_TYPE_EDGE_RISING>;
		interrupt-names = "bam-irq", "core-irq";
		qcom,bam-pipe-pair = <2>;
		qcom,offload-ops-support;
		qcom,bam-pipe-offload-cpb-hlos = <1>;
		qcom,bam-pipe-offload-hlos-cpb = <3>;
		qcom,bam-pipe-offload-hlos-cpb-1 = <8>;
		qcom,bam-pipe-offload-hlos-hlos = <4>;
		qcom,bam-pipe-offload-hlos-hlos-1 = <9>;
		qcom,ce-hw-instance = <0>;
		qcom,ce-device = <0>;
		qcom,ce-hw-shared;
		qcom,bam-ee = <0>;
		qcom,smmu-s1-enable;
		qcom,no-clock-support;
		interconnect-names = "data_path";
		interconnects = <&aggre_noc MASTER_CRYPTO &mc_virt SLAVE_EBI1>;
		iommus = <&apps_smmu 0x0080 0x0>,
			<&apps_smmu 0x0081 0x0>;
		qcom,iommu-dma = "atomic";
		dma-coherent;

		qcom_cedev_ns_cb {
			compatible = "qcom,qcedev,context-bank";
			label = "ns_context";
			iommus = <&apps_smmu 0x0081 0x0>;
			dma-coherent;
		};

		qcom_cedev_s_cb {
			compatible = "qcom,qcedev,context-bank";
			label = "secure_context";
			iommus = <&apps_smmu 0x0083 0x0>;
			qcom,iommu-vmid = <0x9>;
			qcom,secure-context-bank;
			dma-noncoherent;
		};
	};

	rng: rng@10c3000 {
		compatible = "qcom,trng";
		reg = <0x0 0x10c3000 0x0 0x1000>;
	};

	qcom,tmecom-qmp-client {
		compatible = "qcom,tmecom-qmp-client";
		mboxes = <&qmp_tme 0>;
		mbox-names = "tmecom";
		label = "tmecom";
		depends-on-supply = <&qmp_tme>;
	};

	clocks {
		xo_board: xo_board {
			compatible = "fixed-clock";
			clock-frequency = <76800000>;
			clock-output-names = "xo_board";
			#clock-cells = <0>;
		};

		sleep_clk: sleep_clk {
			compatible = "fixed-clock";
			clock-frequency = <32000>;
			clock-output-names = "sleep_clk";
			#clock-cells = <0>;
		};

		pcie_0_pipe_clk: pcie_0_pipe_clk {
			compatible = "fixed-clock";
			clock-frequency = <1000>;
			clock-output-names = "pcie_0_pipe_clk";
			#clock-cells = <0>;
		};

		ufs_phy_rx_symbol_0_clk: ufs_phy_rx_symbol_0_clk {
			compatible = "fixed-clock";
			clock-frequency = <1000>;
			clock-output-names = "ufs_phy_rx_symbol_0_clk";
			#clock-cells = <0>;
		};

		ufs_phy_rx_symbol_1_clk: ufs_phy_rx_symbol_1_clk {
			compatible = "fixed-clock";
			clock-frequency = <1000>;
			clock-output-names = "ufs_phy_rx_symbol_1_clk";
			#clock-cells = <0>;
		};

		ufs_phy_tx_symbol_0_clk: ufs_phy_tx_symbol_0_clk {
			compatible = "fixed-clock";
			clock-frequency = <1000>;
			clock-output-names = "ufs_phy_tx_symbol_0_clk";
			#clock-cells = <0>;
		};
	};

	camcc: clock-controller@ade0000 {
		compatible = "qcom,chora-camcc", "syscon";
		reg = <0x0 0xade0000 0x0 0x20000>;
		reg-name = "cc_base";
		vdd_cx-supply = <&VDD_CX_LEVEL>;
		vdd_mx-supply = <&VDD_MX_LEVEL>;
		clocks = <&rpmhcc RPMH_CXO_CLK>,
			<&gcc GCC_CAMERA_AHB_CLK>;
		clock-names = "bi_tcxo", "iface";
		interconnects = <&mmss_noc MASTER_CAMNOC_HF &mmss_noc SLAVE_MNOC_HF_MEM_NOC>;
		interconnect-names = "mmnoc";
		#clock-cells = <1>;
		#reset-cells = <1>;
		#power-domain-cells = <1>;
	};

	dispcc: clock-controller@af00000 {
		compatible = "qcom,chora-dispcc", "syscon";
		reg = <0x0 0xaf00000 0x0 0x20000>;
		reg-name = "cc_base";
		vdd_cx-supply = <&VDD_CX_LEVEL>;
		vdd_mx-supply = <&VDD_MX_LEVEL>;
		clocks = <&rpmhcc RPMH_CXO_CLK>,
			 <&sleep_clk>,
			 <&gcc GCC_DISP_AHB_CLK>,
			 <&gcc GCC_DISP_GPLL0_DIV_CLK_SRC>;
		clock-names = "bi_tcxo",
			      "sleep_clk",
			      "iface",
			      "gcc_disp_gpll0_div_clk_src";
		#clock-cells = <1>;
		#reset-cells = <1>;
		#power-domain-cells = <1>;
	};

	gcc: clock-controller@100000 {
		compatible = "qcom,chora-gcc", "syscon";
		reg = <0x0 0x100000 0x0 0x1f4200>;
		reg-name = "cc_base";
		vdd_cx-supply = <&VDD_CX_LEVEL>;
		vdd_mx-supply = <&VDD_MX_LEVEL>;
		clocks = <&rpmhcc RPMH_CXO_CLK>,
			 <&pcie_0_pipe_clk>,
			 <&sleep_clk>,
			 <&ufs_phy_rx_symbol_0_clk>,
			 <&ufs_phy_rx_symbol_1_clk>,
			 <&ufs_phy_tx_symbol_0_clk>;
		clock-names = "bi_tcxo",
			      "pcie_0_pipe_clk",
			      "sleep_clk",
			      "ufs_phy_rx_symbol_0_clk",
			      "ufs_phy_rx_symbol_1_clk",
			      "ufs_phy_tx_symbol_0_clk";
		#clock-cells = <1>;
		#reset-cells = <1>;
		#power-domain-cells = <1>;
	};

	gpucc: clock-controller@3d90000 {
		compatible = "qcom,chora-gpucc", "syscon";
		reg = <0x0 0x3d90000 0x0 0x9800>;
		reg-name = "cc_base";
		vdd_cx-supply = <&VDD_CX_LEVEL>;
		vdd_mx-supply = <&VDD_MX_LEVEL>;
		clocks = <&rpmhcc RPMH_CXO_CLK>,
			 <&gcc GCC_GPU_GPLL0_CLK_SRC>,
			 <&gcc GCC_GPU_GPLL0_DIV_CLK_SRC>;
		clock-names = "bi_tcxo",
			      "gpll0_out_main",
			      "gpll0_out_main_div";
		#clock-cells = <1>;
		#reset-cells = <1>;
		#power-domain-cells = <1>;
	};

	gxclkctl: clock-controller@3d68024 {
		compatible = "qcom,chora-gx_clkctl", "syscon";
		reg = <0x0 0x3d68024 0x0 0x8>;
		reg-name = "cc_base";
		power-domains = <&gpucc GPU_CC_CX_GDSC>;
		vdd_gfx-supply = <&VDD_GFX_LEVEL>;
		#power-domain-cells = <1>;
	};

	tcsrcc: clock-controller@1ff1100 {
		compatible = "qcom,chora-tcsrcc", "syscon";
		reg = <0x0 0x1ff1100 0x0 0x20>;
		reg-name = "cc_base";
		#clock-cells = <1>;
		#reset-cells = <1>;
	};

	videocc: clock-controller@aaf0000 {
		compatible = "qcom,chora-videocc", "syscon";
		reg = <0x0 0xaaf0000 0x0 0x10000>;
		reg-name = "cc_base";
		vdd_cx-supply = <&VDD_CX_LEVEL>;
		vdd_mx-supply = <&VDD_MX_LEVEL>;
		clocks = <&rpmhcc RPMH_CXO_CLK>,
			 <&rpmhcc RPMH_CXO_CLK_A>,
			<&gcc GCC_VIDEO_AHB_CLK>,
			<&sleep_clk>;
		clock-names = "bi_tcxo",
				"bi_tcxo_ao",
				"iface",
				"sleep_clk";
		interconnects = <&mmss_noc MASTER_CAMNOC_HF &mmss_noc SLAVE_MNOC_HF_MEM_NOC>;
		interconnect-names = "mmnoc";
		#clock-cells = <1>;
		#reset-cells = <1>;
		#power-domain-cells = <1>;
	};

	apsscc: syscon@17a80000 {
		compatible = "syscon";
		reg = <0x0 0x17aa0000 0x0 0x1c>;
	};

	mccc: syscon@240ba000 {
		compatible = "syscon";
		reg = <0x0 0x240ba000 0x0 0x54>;
	};

	gxclkctldebugcc: syscon@3d68000 {
		compatible = "syscon";
		reg = <0x0 0x3d68000 0x0 0x1000>;
	};

	debugcc: clock-controller@0 {
		compatible = "qcom,chora-debugcc";
		qcom,apsscc = <&apsscc>;
		qcom,camcc = <&camcc>;
		qcom,dispcc = <&dispcc>;
		qcom,gcc = <&gcc>;
		qcom,gpucc = <&gpucc>;
		qcom,gxclkctl = <&gxclkctldebugcc>;
		qcom,tcsrcc = <&tcsrcc>;
		qcom,videocc = <&videocc>;
		qcom,mccc = <&mccc>;
		clocks = <&rpmhcc RPMH_CXO_CLK>,
			 <&camcc 0>,
			 <&dispcc 0>,
			 <&gcc 0>,
			 <&gpucc 0>,
			 <&videocc 0>;
		clock-names = "xo_clk_src",
			      "camcc",
			      "dispcc",
			      "gcc",
			      "gpucc",
			      "videocc";
		#clock-cells = <1>;
	};

	cpufreq_hw: qcom,cpufreq-hw {
		compatible = "qcom,cpufreq-epss";
		reg = <0x0 0x17d91000 0x0 0x1000>,
		      <0x0 0x17d92000 0x0 0x1000>;
		reg-names = "freq-domain0",
			    "freq-domain1";
		clocks = <&rpmhcc RPMH_CXO_CLK>, <&gcc GCC_GPLL0>;
		clock-names = "xo", "alternate";
		interrupts = <GIC_SPI 30 IRQ_TYPE_LEVEL_HIGH>,
			     <GIC_SPI 31 IRQ_TYPE_LEVEL_HIGH>;
		interrupt-names = "dcvsh0_int",
				  "dcvsh1_int";
		#freq-domain-cells = <1>;
	};

	qcom,cpufreq-hw-debug {
		compatible = "qcom,cpufreq-hw-epss-debug";
		qcom,freq-hw-domain = <&cpufreq_hw 0>,
				      <&cpufreq_hw 1>;
	};

	mmio_sram: mmio-sram@17D09100 {
		#address-cells = <1>;
		#size-cells = <1>;
		compatible = "mmio-sram";
		reg = <0x0 0x17D09100 0x0 0x200>;
		ranges = <0 0x0 0x17D09100 0x200>;

		cpu_scp_lpri: scmi-shmem@0 {
			compatible = "arm,scmi-shmem";
			reg = <0x0 0x200>;
		};
	};

	cpucp: qcom,cpucp@17400000 {
		#address-cells = <2>;
		#size-cells = <2>;
		compatible = "qcom,cpucp";
		reg =   <0x0 0x17400000 0x0 0x10>,
			<0x0 0x17d90000 0x0 0x2000>;
		reg-names = "tx", "rx";
		#mbox-cells = <1>;
		interrupts = <GIC_SPI 62 IRQ_TYPE_LEVEL_HIGH>;
	};

	scmi: qcom,scmi {
		#address-cells = <1>;
		#size-cells = <0>;
		compatible = "arm,scmi";
		mboxes = <&cpucp 0>;
		mbox-names = "tx";
		shmem = <&cpu_scp_lpri>;

		scmi_qcom: protocol@80 {
			reg = <0x80>;
			#clock-cells = <1>;
		};
	};

	cpucp_log: qcom,cpucp_log@81840000 {
		compatible = "qcom,cpucp-log";
		reg =	<0x0 0x81840000 0x0 0x10000>,
			<0x0 0x81850000 0x0 0x10000>;
		mboxes = <&cpucp 1>;
		qcom,log-type = <0>;
	};

	qcom_pmu: qcom,pmu {
		compatible = "qcom,pmu";
		qcom,pmu-events-tbl =
			< 0x0008 0xFF 0xFF 0xFF >,
			< 0x0011 0xFF 0xFF 0xFF >,
			< 0x0017 0xFF 0xFF 0xFF >,
			< 0x002A 0xFF 0xFF 0xFF >;
	};

	ddr_freq_table: ddr-freq-table {
		ddr4 {
			qcom,ddr-type = <7>;
			qcom,freq-tbl =
				<  547200 >,
				<  768000 >,
				< 1017600 >,
				< 1353600 >,
				< 1555200 >,
				< 1708800 >,
				< 2092800 >;
		};

		ddr5 {
			qcom,ddr-type = <8>;
			qcom,freq-tbl =
				<  547200 >,
				<  768000 >,
				< 1555200 >,
				< 1708800 >,
				< 2092800 >,
				< 2736000 >,
				< 3187200 >;
		};
	};

	ddrqos_freq_table: ddrqos-freq-table {
		qcom,freq-tbl =
		< 0 >,
		< 1 >;
	};

	qcom_dcvs: qcom,dcvs {
		compatible = "qcom,dcvs";
		#address-cells = <1>;
		#size-cells = <1>;
		ranges;

		qcom_l3_dcvs_hw: l3 {
			compatible = "qcom,dcvs-hw";
			qcom,dcvs-hw-type = <2>;
			qcom,bus-width = <32>;
			reg = <0x17d90000 0x4000>, <0x17d90100 0xa0>;
			reg-names = "l3-base", "l3tbl-base";

			l3_dcvs_sp: sp {
				compatible = "qcom,dcvs-path";
				qcom,dcvs-path-type = <0>;
				qcom,shared-offset = <0x0090>;
			};
		};

		qcom_ddr_dcvs_hw: ddr {
			compatible = "qcom,dcvs-hw";
			qcom,dcvs-hw-type = <0>;
			qcom,bus-width = <4>;
			qcom,freq-tbl = <&ddr_freq_table>;

			ddr_dcvs_sp: sp {
				compatible = "qcom,dcvs-path";
				qcom,dcvs-path-type = <0>;
				interconnects = <&gem_noc MASTER_APPSS_PROC
						 &mc_virt SLAVE_EBI1>;
			};

			ddr_dcvs_fp: fp {
				compatible = "qcom,dcvs-path";
				qcom,dcvs-path-type = <1>;
				qcom,fp-voter = <&dcvs_fp>;
			};
		};

		qcom_ddrqos_dcvs_hw: ddrqos {
			compatible = "qcom,dcvs-hw";
			qcom,dcvs-hw-type = <3>;
			qcom,bus-width = <1>;
			qcom,freq-tbl = <&ddrqos_freq_table>;

			ddrqos_dcvs_sp: sp {
				compatible = "qcom,dcvs-path";
				qcom,dcvs-path-type = <0>;
				interconnects = <&gem_noc MASTER_APPSS_PROC
					 &mc_virt SLAVE_EBI1>;
			};
		};
	};

	qcom_memlat: qcom,memlat {
		compatible = "qcom,memlat";

		ddr {
			compatible = "qcom,memlat-grp";
			qcom,target-dev = <&qcom_ddr_dcvs_hw>;
			qcom,sampling-path = <&ddr_dcvs_fp>;
			qcom,miss-ev = <0x2A>;

			silver {
				compatible = "qcom,memlat-mon";
				qcom,cpulist = <&CPU0 &CPU1 &CPU2 &CPU3>;
				qcom,sampling-enabled;
				ddr4-tbl {
					qcom,ddr-type = <7>;
					qcom,cpufreq-memfreq-tbl =
						< 1113600  547000 >,
						< 1401600  768000 >,
						< 1708800 1017000 >,
						< 2016000 1353000 >;
				};

				ddr5-tbl {
					qcom,ddr-type = <8>;
					qcom,cpufreq-memfreq-tbl =
						< 1113600  547000 >,
						< 1401600  768000 >,
						< 1708800 1555000 >,
						< 2016000 1708000 >;
				};
			};

			gold {
				compatible = "qcom,memlat-mon";
				qcom,cpulist = <&CPU4 &CPU5 &CPU6 &CPU7>;
				qcom,sampling-enabled;
				ddr4-tbl {
					qcom,ddr-type = <7>;
					qcom,cpufreq-memfreq-tbl =
						<  960000  547000 >,
						< 1228800 1017000 >,
						< 1651200 1353600 >,
						< 1900800 1555000 >,
						< 2304000 1708000 >,
						< 2611200 2092000 >;
				};

				ddr5-tbl {
					qcom,ddr-type = <8>;
					qcom,cpufreq-memfreq-tbl =
						<  960000  547200 >,
						< 1228800  768000 >,
						< 1651200 1555200 >,
						< 1900800 1708000 >,
						< 2304000 2092800 >,
						< 2611200 3187200 >;
				};
			};

			silver-compute {
				compatible = "qcom,memlat-mon";
				qcom,cpulist = <&CPU0 &CPU1 &CPU2 &CPU3>;
				qcom,sampling-enabled;
				qcom,compute-mon;
				ddr4-tbl {
					qcom,ddr-type = <7>;
					qcom,cpufreq-memfreq-tbl =
						< 1497600  547000 >,
						< 2016000  768000 >;
				};

				ddr5-tbl {
					qcom,ddr-type = <8>;
					qcom,cpufreq-memfreq-tbl =
						< 1497600  547000 >,
						< 2016000  768000 >;
				};
			};

			gold-compute {
				compatible = "qcom,memlat-mon";
				qcom,cpulist = <&CPU4 &CPU5 &CPU6 &CPU7>;
				qcom,sampling-enabled;
				qcom,compute-mon;
				ddr4-tbl {
					qcom,ddr-type = <7>;
					qcom,cpufreq-memfreq-tbl =
						<  960000  547200 >,
						< 1190400  768000 >,
						< 1612800 1017000 >,
						< 1900800 1353000 >,
						< 2246400 1708800 >,
						< 2611200 2092000 >;
				};

				ddr5-tbl {
					qcom,ddr-type = <8>;
					qcom,cpufreq-memfreq-tbl =
						<  960000  547000 >,
						< 1190400  768000 >,
						< 1612800 1555200 >,
						< 1900800 1708000 >,
						< 2246400 2092800 >,
						< 2611200 3187200 >;
				};
			};
		};

		l3 {
			compatible = "qcom,memlat-grp";
			qcom,target-dev = <&qcom_l3_dcvs_hw>;
			qcom,sampling-path = <&l3_dcvs_sp>;
			qcom,miss-ev = <0x17>;

			silver {
				compatible = "qcom,memlat-mon";
				qcom,cpulist = <&CPU0 &CPU1 &CPU2 &CPU3>;
				qcom,sampling-enabled;
				qcom,cpufreq-memfreq-tbl =
					< 499200   384000 >,
					< 652800   537600 >,
					< 806400   652800 >,
					< 960000   806400 >,
					< 1113600  940800 >,
					< 1401600 1190400 >,
					< 1555200 1305600 >,
					< 1708800 1401600 >,
					< 1804800 1459200 >,
					< 2016000 1555000 >;
			};

			gold {
				compatible = "qcom,memlat-mon";
				qcom,cpulist = <&CPU4 &CPU5 &CPU6 &CPU7>;
				qcom,sampling-enabled;
				qcom,cpufreq-memfreq-tbl =
					< 499200   384000 >,
					< 960000   537600 >,
					< 1056000  806400 >,
					< 1363200  940800 >,
					< 1785600 1190400 >,
					< 1900800 1401600 >,
					< 2304000 1459200 >,
					< 2611200 1555000 >;
			};

			gold-compute {
				compatible = "qcom,memlat-mon";
				qcom,cpulist = <&CPU4 &CPU5 &CPU6 &CPU7>;
				qcom,sampling-enabled;
				qcom,compute-mon;
				qcom,cpufreq-memfreq-tbl =
					< 2035200  384000 >,
					< 2611200 1459200 >;
			};
		};

		ddrqos {
			compatible = "qcom,memlat-grp";
			qcom,target-dev = <&qcom_ddrqos_dcvs_hw>;
			qcom,sampling-path = <&ddrqos_dcvs_sp>;
			qcom,miss-ev = <0x2A>;

			ddrqos_gold_lat: gold {
				compatible = "qcom,memlat-mon";
				qcom,cpulist = <&CPU4 &CPU5 &CPU6 &CPU7>;
				qcom,sampling-enabled;
				qcom,cpufreq-memfreq-tbl =
					< 2300000 0 >,
					< 3000000 1 >;
			};
		};
	};

	bwmon_ddr: qcom,bwmon-ddr@24091000 {
		compatible = "qcom,bwmon5";
		reg = <0x0 0x24091000 0x0 0x1000>;
		reg-names = "base";
		interrupts = <GIC_SPI 81 IRQ_TYPE_LEVEL_HIGH>;
		qcom,hw-timer-hz = <19200000>;
		qcom,count-unit = <0x10000>;
		qcom,target-dev = <&qcom_ddr_dcvs_hw>;
	};

	qcom,msm-adsprpc-mem {
		compatible = "qcom,msm-adsprpc-mem-region";
		memory-region = <&adsp_mem_heap>;
		restrict-access;
	};

	qcom,lcp-dare-dare-pool {
		compatible = "qcom,mem-prot-pool";
		memory-region = <&lcp_dare_pool>;
		qcom,lcp-dare;
	};

	adsp_sleepmon: adsp-sleepmon {
		compatible = "qcom,adsp-sleepmon";
		qcom,rproc-handle = <&adsp_pas>;
	};

	adsp_pas: remoteproc-adsp@3000000 {
		compatible = "qcom,chora-adsp-pas";
		reg = <0x0 0x03000000 0x0 0x10000>;

		clocks = <&rpmhcc RPMH_CXO_CLK>;
		clock-names = "xo";

		cx-supply = <&VDD_LPI_CX_LEVEL>;
		cx-uV-uA = <RPMH_REGULATOR_LEVEL_NOM 0>;
		mx-supply = <&VDD_LPI_MX_LEVEL>;
		mx-uV-uA = <RPMH_REGULATOR_LEVEL_NOM 0>;
		reg-names = "cx", "mx";

		qcom,qmp = <&aoss_qmp>;

		interconnects = <&lpass_ag_noc MASTER_LPASS_PROC &mc_virt SLAVE_EBI1>,
				<&aggre_noc MASTER_CRYPTO &mc_virt SLAVE_EBI1>;
		interconnect-names = "rproc_ddr", "crypto_ddr";

		memory-region = <&adspslpi_mem &q6_adsp_dtb_mem>;
		firmware-name = "adsp.mdt", "adsp_dtb.mdt";

		/* Inputs from ssc */
		interrupts-extended = <&pdc 6 IRQ_TYPE_EDGE_RISING>,
					<&adsp_smp2p_in 0 0>,
					<&adsp_smp2p_in 2 0>,
					<&adsp_smp2p_in 1 0>,
					<&adsp_smp2p_in 3 0>,
					<&adsp_smp2p_in 7 0>;

		interrupt-names = "wdog",
				"fatal",
				"handover",
				"ready",
				"stop-ack",
				"shutdown-ack";

		/* Outputs to turing */
		qcom,smem-states = <&adsp_smp2p_out 0>;
		qcom,smem-state-names = "stop";

		status = "ok";

		remoteproc_adsp_glink: glink-edge {
			qcom,remote-pid = <2>;
			transport = "smem";
			mboxes = <&ipcc_mproc IPCC_CLIENT_LPASS
				  IPCC_MPROC_SIGNAL_GLINK_QMP>;
			mbox-names = "adsp_smem";
			interrupt-parent = <&ipcc_mproc>;
			interrupts = <IPCC_CLIENT_LPASS
				      IPCC_MPROC_SIGNAL_GLINK_QMP
				      IRQ_TYPE_EDGE_RISING>;

			label = "adsp";
			qcom,glink-label = "lpass";

			qcom,adsp_qrtr {
				qcom,glink-channels = "IPCRTR";
				qcom,net-id = <2>;
				qcom,intents = <0x800  5
						0x2000 3
						0x4400 2>;

				qcom,no-wake-svc = <0x190>;
			};

			qcom,msm_adspsleepmon_rpmsg {
				compatible = "qcom,msm-adspsleepmon-rpmsg";
				qcom,glink-channels = "sleepmonglink-apps-adsp";
				qcom,intents = <0x1000 8>;
			};
		};
	};

	modem_pas: remoteproc-mss@4080000 {
		compatible = "qcom,chora-modem-pas";
		reg = <0x0 0x04080000 0x0 0x10000>;

		clocks = <&rpmhcc RPMH_CXO_CLK>;
		clock-names = "xo";

		cx-supply = <&VDD_CX_LEVEL>;
		cx-uV-uA = <RPMH_REGULATOR_LEVEL_TURBO 100000>;
		mx-supply = <&VDD_MX_LEVEL>;
		mx-uV-uA = <RPMH_REGULATOR_LEVEL_TURBO 100000>;
		mss-supply = <&VDD_MODEM_LEVEL>;
		mss-uV-uA = <RPMH_REGULATOR_LEVEL_NOM_L1 100000>;
		reg-names = "cx", "mx", "mss";

		qcom,qmp = <&aoss_qmp>;

		interconnects = <&mc_virt MASTER_LLCC &mc_virt SLAVE_EBI1>,
				<&aggre_noc MASTER_CRYPTO &mc_virt SLAVE_EBI1>;
		interconnect-names = "rproc_ddr", "crypto_ddr";

		memory-region = <&mpss_mem &q6_mpss_dtb_mem &system_cma>;
		firmware-name = "modem.mdt", "modem_dtb.mdt";

		/* Inputs from mss */
		interrupts-extended = <&intc GIC_SPI 264 IRQ_TYPE_EDGE_RISING>,
					<&modem_smp2p_in 0 0>,
					<&modem_smp2p_in 2 0>,
					<&modem_smp2p_in 1 0>,
					<&modem_smp2p_in 3 0>,
					<&modem_smp2p_in 7 0>;

		interrupt-names = "wdog",
				"fatal",
				"handover",
				"ready",
				"stop-ack",
				"shutdown-ack";

		/* Outputs to turing */
		qcom,smem-states = <&modem_smp2p_out 0>;
		qcom,smem-state-names = "stop";

		status = "ok";

		glink-edge {
			qcom,remote-pid = <1>;
			transport = "smem";
			mboxes = <&ipcc_mproc IPCC_CLIENT_MPSS
				  IPCC_MPROC_SIGNAL_GLINK_QMP>;
			mbox-names = "mpss_smem";
			interrupt-parent = <&ipcc_mproc>;
			interrupts = <IPCC_CLIENT_MPSS
				      IPCC_MPROC_SIGNAL_GLINK_QMP
				      IRQ_TYPE_EDGE_RISING>;

			label = "modem";
			qcom,glink-label = "mpss";

			qcom,modem_qrtr {
				qcom,glink-channels = "IPCRTR";
				qcom,low-latency;
				qcom,intents = <0x800  5
						0x2000 3
						0x4400 2>;
			};

			qcom,modem_ds {
				qcom,glink-channels = "DS";
				qcom,intents = <0x4000 0x2>;
			};
		};
	};

	clk_virt: interconnect@0 {
		compatible = "qcom,chora-clk_virt";
		#interconnect-cells = <1>;
		qcom,bcm-voter-names = "hlos";
		qcom,bcm-voters = <&apps_bcm_voter>;
	};

	mc_virt: interconnect@1 {
		compatible = "qcom,chora-mc_virt";
		#interconnect-cells = <1>;
		qcom,bcm-voter-names = "hlos", "disp";
		qcom,bcm-voters = <&apps_bcm_voter>, <&disp_bcm_voter>;
	};

	aggre_noc: interconnect@1700000 {
		compatible = "qcom,chora-aggre1_noc";
		reg = <0x0 0x01700000 0x0 0x35400>;
		#interconnect-cells = <1>;
		qcom,bcm-voter-names = "hlos";
		qcom,bcm-voters = <&apps_bcm_voter>;
		clocks = <&gcc GCC_SNOC_CNOC_USB2_CLK>,
			 <&gcc GCC_AGGRE_UFS_PHY_AXI_CLK>,
			 <&rpmhcc RPMH_IPA_CLK>;
	};

	config_noc: interconnect@1600000 {
		compatible = "qcom,chora-cnoc_cfg";
		reg = <0x0 0x01600000 0x0 0x7200>;
		#interconnect-cells = <1>;
		qcom,bcm-voter-names = "hlos";
		qcom,bcm-voters = <&apps_bcm_voter>;
	};

	cnoc_main: interconnect@1500000 {
		compatible = "qcom,chora-cnoc_main";
		reg = <0x0 0x01500000 0x0 0x16200>;
		#interconnect-cells = <1>;
		qcom,bcm-voter-names = "hlos";
		qcom,bcm-voters = <&apps_bcm_voter>;
	};

	gem_noc: interconnect@24100000 {
		compatible = "qcom,chora-gem_noc";
		reg = <0x0 0x24100000 0x0 0xff080>;
		#interconnect-cells = <1>;
		qcom,bcm-voter-names = "hlos", "disp";
		qcom,bcm-voters = <&apps_bcm_voter>, <&disp_bcm_voter>;
	};

	lpass_ag_noc: interconnect@3C40000 {
		compatible = "qcom,chora-lpass_ag_noc";
		reg = <0x0 0x03c40000 0x0 0x17200>;
		#interconnect-cells = <1>;
		qcom,bcm-voter-names = "hlos";
		qcom,bcm-voters = <&apps_bcm_voter>;
	};

	mmss_noc: interconnect@1400000 {
		compatible = "qcom,chora-mmss_noc";
		reg = <0x0 0x01400000 0x0 0xdb400>;
		#interconnect-cells = <1>;
		qcom,bcm-voter-names = "hlos", "disp";
		qcom,bcm-voters = <&apps_bcm_voter>, <&disp_bcm_voter>;
	};

	pcie_anoc: interconnect@16C0000 {
		compatible = "qcom,chora-pcie_anoc";
		reg = <0x0 0x016c0000 0x0 0xf080>;
		#interconnect-cells = <1>;
		qcom,bcm-voter-names = "hlos";
		qcom,bcm-voters = <&apps_bcm_voter>;
		clocks = <&gcc GCC_AGGRE_NOC_PCIE_AXI_CLK>,
			 <&gcc GCC_CFG_NOC_PCIE_ANOC_AHB_CLK>;
	};

	system_noc: interconnect@1680000 {
		compatible = "qcom,chora-system_noc";
		reg = <0x0 0x01680000 0x0 0x1f080>;
		#interconnect-cells = <1>;
		qcom,bcm-voter-names = "hlos";
		qcom,bcm-voters = <&apps_bcm_voter>;
	};

	wpss_pas: remoteproc-wpss@99300000 {
		compatible = "qcom,chora-wpss-pas";
		reg = <0x0 0x99300000 0x0 0x10000>;

		status = "ok";

		memory-region = <&wpss_mem>;

		firmware-name = "wcn6450/wpss.mdt";

		clocks = <&rpmhcc RPMH_CXO_CLK>;
		clock-names = "xo";

		cx-supply = <&VDD_CX_LEVEL>;
		cx-uV-uA = <RPMH_REGULATOR_LEVEL_TURBO 100000>;
		mx-supply = <&VDD_MX_LEVEL>;
		mx-uV-uA = <RPMH_REGULATOR_LEVEL_TURBO 100000>;
		reg-names = "cx","mx";

		qcom,qmp = <&aoss_qmp>;

		/* Inputs from wpss */
		interrupts-extended = <&intc GIC_SPI 579 IRQ_TYPE_EDGE_RISING>,
				      <&wpss_smp2p_in 0 0>,
				      <&wpss_smp2p_in 2 0>,
				      <&wpss_smp2p_in 1 0>,
				      <&wpss_smp2p_in 3 0>,
				      <&wpss_smp2p_in 7 0>;

		interrupt-names = "wdog",
				   "fatal",
				   "handover",
				   "ready",
				   "stop-ack",
				   "shutdown-ack";

		/* Outputs to wpss */
		qcom,smem-states = <&wpss_smp2p_out 0>;
		qcom,smem-state-names = "stop";

		glink-edge {
			qcom,remote-pid = <13>;
			transport = "smem";
			mboxes = <&ipcc_mproc IPCC_CLIENT_WPSS
				  IPCC_MPROC_SIGNAL_GLINK_QMP>;
			mbox-names = "wpss_smem";
			interrupt-parent = <&ipcc_mproc>;
			interrupts = <IPCC_CLIENT_WPSS
					  IPCC_MPROC_SIGNAL_GLINK_QMP
					  IRQ_TYPE_EDGE_RISING>;

			label = "wpss";
			qcom,glink-label = "wpss";

			qcom,wpss_qrtr {
				qcom,glink-channels = "IPCRTR";
				qcom,intents = <0x800  5
						0x2000 3
						0x4400 2>;
			};
		};

	};

	qcom,rmtfs_sharedmem@0 {
		compatible = "qcom,sharedmem-uio";
		reg = <0x0 0x0 0x0 0x280000>;
		reg-names = "rmtfs";
		qcom,client-id = <0x00000001>;
	};

	sdhc_2_dma_resv: sdhc_2_dma_resv_region {
		/*
		 * Restrict IOVA mappings for SDHC2 buffers to the 256 MB region
		 * from 0x40000000 - 0x4fffffff.
		 */
		iommu-addresses = <&sdhc_2 0x0 0x0 0x0 0x40000000>,
				  <&sdhc_2 0x0 0x50000000 0xffffffff 0xb0000000>;
	};

	sdhc2_opp_table: sdhc2-opp-table {
		compatible = "operating-points-v2";

		opp-100000000 {
			opp-hz = /bits/ 64 <100000000>;
			opp-peak-kBps = <160000 100000>;
			opp-avg-kBps = <50000 0>;
		};

		opp-202000000 {
			opp-hz = /bits/ 64 <202000000>;
			opp-peak-kBps = <200000 120000>;
			opp-avg-kBps = <104000 0>;
		};
	};

	sdhc_2: sdhci@8804000 {
		compatible = "qcom,sdhci-msm-v5";
		#address-cells = <2>;
		#size-cells = <2>;
		reg = <0x0 0x8804000 0x0 0x1000>;
		reg-names = "hc";

		interrupts = <GIC_SPI 204 IRQ_TYPE_LEVEL_HIGH>,
				<GIC_SPI 125 IRQ_TYPE_LEVEL_HIGH>;
		interrupt-names = "hc_irq", "pwr_irq";

		bus-width = <4>;
		no-sdio;
		no-mmc;
		qcom,restore-after-cx-collapse;
		qcom,uses_level_shifter;

		clocks = <&gcc GCC_SDCC2_AHB_CLK>,
			 <&gcc GCC_SDCC2_APPS_CLK>;
		clock-names = "iface", "core";

		/*
		 * DLL HSR settings. Refer go/hsr - <Target> DLL settings.
		 * Note that the DLL_CONFIG_2 value is not passed from the
		 * device tree, but it is calculated in the driver.
		 */
		qcom,dll-hsr-list = <0x0007442C 0x0 0x10
					0x090106C0 0x80040868>;

		iommus = <&apps_smmu 0x140 0x0>;
		qcom,iommu-dma = "fastmap";
		dma-coherent;
		memory-region = <&sdhc_2_dma_resv>;
		qcom,iommu-geometry = <0x0 0x40000000 0x0 0x10000000>;

		interconnects = <&aggre_noc MASTER_SDCC_2 &mc_virt SLAVE_EBI1>,
			      <&gem_noc MASTER_APPSS_PROC &config_noc SLAVE_SDCC_2>;
		interconnect-names = "sdhc-ddr", "cpu-sdhc";
		operating-points-v2 = <&sdhc2_opp_table>;

		cd-gpios = <&tlmm 59 GPIO_ACTIVE_LOW>;
		resets = <&gcc GCC_SDCC2_BCR>;
		reset-names = "core_reset";

		status = "disabled";

		qos0 {
			mask = <0xf0>;
			vote = <44>;
		};

		qos1 {
			mask = <0x0f>;
			vote = <44>;
		};
	};

	ufsphy_mem: ufsphy_mem@1d80000 {
		#address-cells = <2>;
		#size-cells = <2>;
		reg = <0x0 0x1d80000 0x0 0x2000>;
		reg-names = "phy_mem";
		#phy-cells = <0>;

		power-domains = <&gcc GCC_UFS_MEM_PHY_GDSC>;
		lanes-per-direction = <2>;
		clock-names = "ref_clk_src",
			"ref_aux_clk", "qref_clk",
			"rx_sym0_mux_clk", "rx_sym1_mux_clk", "tx_sym0_mux_clk",
			"rx_sym0_phy_clk", "rx_sym1_phy_clk", "tx_sym0_phy_clk";
		clocks = <&rpmhcc RPMH_CXO_CLK>,
			<&gcc GCC_UFS_PHY_PHY_AUX_CLK>,
			<&tcsrcc TCSR_UFS_PHY_CLKREF_EN>,
			<&gcc GCC_UFS_PHY_RX_SYMBOL_0_CLK_SRC>,
			<&gcc GCC_UFS_PHY_RX_SYMBOL_1_CLK_SRC>,
			<&gcc GCC_UFS_PHY_TX_SYMBOL_0_CLK_SRC>,
			<&ufs_phy_rx_symbol_0_clk>,
			<&ufs_phy_rx_symbol_1_clk>,
			<&ufs_phy_tx_symbol_0_clk>;
		resets = <&ufshc_mem 0>;
		status = "disabled";
	};

	ufshc_dma_resv: ufshc_dma_resv_region {
		/*
		 * Restrict IOVA mappings for UFSHC buffers to the 3 GB region
		 * from 0x1000 - 0xffffffff.
		 */
		iommu-addresses = <&ufshc_mem 0x0 0x0 0x0 0x1000>;
	};

	ufshc_opp_table: ufshc-opp-table {
		compatible = "operating-points-v2";

		// LOW_SVS
		opp-100000000 {
			opp-hz = /bits/ 64 <75000000>,
				 /bits/ 64 <0>,
				 /bits/ 64 <0>,
				 /bits/ 64 <75000000>,
				 /bits/ 64 <100000000>,
				 /bits/ 64 <0>,
				 /bits/ 64 <0>,
				 /bits/ 64 <0>,
				 /bits/ 64 <0>;
		};

		// NOM/TURBO
		opp-300000000 {
			opp-hz = /bits/ 64 <300000000>,
				 /bits/ 64 <0>,
				 /bits/ 64 <0>,
				 /bits/ 64 <300000000>,
				 /bits/ 64 <403000000>,
				 /bits/ 64 <0>,
				 /bits/ 64 <0>,
				 /bits/ 64 <0>,
				 /bits/ 64 <0>;
		};
	};

	ufshc_mem: ufshc@1d84000 {
		compatible = "qcom,ufshc";
		reg = <0x0 0x1d84000 0x0 0x3000>,
			<0x0 0x1d88000 0x0 0x18000>;
		reg-names = "ufs_mem", "ice";
		interrupts = <GIC_SPI 265 IRQ_TYPE_LEVEL_HIGH>;
		phys = <&ufsphy_mem>;
		phy-names = "ufsphy";
		#reset-cells = <1>;

		qcom,ice-use-hwkm;
		power-domains = <&gcc GCC_UFS_PHY_GDSC>;
		lanes-per-direction = <2>;
		qcom,cluster-mask = <0x0f 0xf0>;

		operating-points-v2 = <&ufshc_opp_table>;
		clock-names =
			"core_clk",
			"bus_aggr_clk",
			"iface_clk",
			"core_clk_unipro",
			"core_clk_ice",
			"ref_clk",
			"tx_lane0_sync_clk",
			"rx_lane0_sync_clk",
			"rx_lane1_sync_clk";
		clocks =
			<&gcc GCC_UFS_PHY_AXI_CLK>,
			<&gcc GCC_AGGRE_UFS_PHY_AXI_CLK>,
			<&gcc GCC_UFS_PHY_AHB_CLK>,
			<&gcc GCC_UFS_PHY_UNIPRO_CORE_CLK>,
			<&gcc GCC_UFS_PHY_ICE_CORE_CLK>,
			<&rpmhcc RPMH_LN_BB_CLK3>,
			<&gcc GCC_UFS_PHY_TX_SYMBOL_0_CLK>,
			<&gcc GCC_UFS_PHY_RX_SYMBOL_0_CLK>,
			<&gcc GCC_UFS_PHY_RX_SYMBOL_1_CLK>;

		interconnects = <&aggre_noc MASTER_UFS_MEM &mc_virt SLAVE_EBI1>,
		      <&gem_noc MASTER_APPSS_PROC &config_noc SLAVE_UFS_MEM_CFG>;
		interconnect-names = "ufs-ddr", "cpu-ufs";

		/* set the dependency that smmu being probed before ufs */
		depends-on-supply = <&apps_smmu>;

		iommus = <&apps_smmu 0x60 0x0>;
		qcom,iommu-geometry = <0x0 0x40000000 0x0 0x10000000>;
		qcom,iommu-dma = "fastmap";
		memory-region = <&ufshc_dma_resv>;
		dma-coherent;

		qcom,max-cpus = <8>;

		reset-gpios = <&tlmm 151 GPIO_ACTIVE_LOW>;
		resets = <&gcc GCC_UFS_PHY_BCR>;
		reset-names = "rst";

		status = "disabled";

		qos0 {
			vote = <44>;
			perf;
		};

		qos1 {
			vote = <44>;
		};
	};

	gunyah-cma-mem {
		compatible = "gunyah-cma-vm-mem";
		memory-region = <&trust_ui_vm_mem &oem_vm_mem>;
		memory-region-names = "trustedvm_cma" , "oemvm_cma";
	};

	qcom,test-dbl-tuivm {
		compatible = "qcom,gh-dbl";
		qcom,label = <0x104>;
	};

	qcom,test-dbl-oemvm {
		compatible = "qcom,gh-dbl";
		qcom,label = <0x105>;
	};

	qcom,test-msgq-tuivm {
		compatible = "qcom,gh-msgq-test";
		gunyah-label = <0x104>;
		qcom,primary;
	};

	qcom,test-msgq-oemvm {
		compatible = "qcom,gh-msgq-test";
		gunyah-label = <0x105>;
		qcom,primary;
	};

	qcom,qrtr-gunyah-tuivm {
		compatible = "qcom,qrtr-gunyah";
		qcom,master;
		gunyah-label = <0x103>;
		peer-name = <2>;
	};

	qcom,gh-qtimer@1742B000 { // APSS_QTMR0_F5V1_QTMR_V1
		compatible = "qcom,gh-qtmr";
		reg = <0x0 0x1742B000 0x0 0x1000>;
		reg-names = "qtmr-base";
		interrupts = <GIC_SPI 13 IRQ_TYPE_LEVEL_HIGH>;
		interrupt-names = "qcom,qtmr-intr";
		qcom,primary;
	};

	qcom,gunyah-panic-notifier {
		compatible = "qcom,gh-panic-notifier";
		qcom,primary-vm;
		gunyah-label = <0x109>;
		peer-name = <2>;
		memory-region = <&vm_comm_mem>;
		shared-buffer-size = <0x1000>;
	};

	dmesg-dump {
		compatible = "qcom,dmesg-dump";
		qcom,primary-vm;
		gunyah-label = <0x107>;
		peer-name = <2>;
		memory-region = <&vm_comm_mem>;
		shared-buffer-size = <0x1000>;
	};

	slimbam: bamdma@3304000 {
		compatible = "qcom,bam-v1.7.0";
		reg = <0x0 0x3304000 0x0 0x20000>, <0x0 0x326b000 0x0 0x1000>;
		reg-names = "bam", "bam_remote_mem";
		num-channels  = <31>;
		interrupts = <GIC_SPI 164 IRQ_TYPE_LEVEL_HIGH>;
		#dma-cells = <1>;
		qcom,controlled-remotely;
		qcom,ee = <1>;
		qcom,num-ees = <2>;
	};

	slim_msm: slim@3340000 {
		compatible = "qcom,slim-ngd-v1.5.0";
		reg = <0x0 0x3340000 0x0 0x2c000>, <0x0 0x326a000 0x0 0x1000>;
		reg-names = "ctrl", "slimbus_remote_mem";
		interrupts = <GIC_SPI 163 IRQ_TYPE_LEVEL_HIGH>;
		dmas = <&slimbam 3>, <&slimbam 4>;
		dma-names = "rx", "tx";
		#address-cells = <1>;
		#size-cells = <0>;
		status = "disabled";
	};

	tlmm-vm-mem-access {
		compatible = "qcom,tlmm-vm-mem-access";
		qcom,master;

		tuivm {
			qcom,label = <0x08>;
			qcom,vmid = <45>;
			tlmm-vm-gpio-list = <
					/* Touch gpio pins */
					&tlmm 0 0
					&tlmm 1 0
					&tlmm 19 0
					&tlmm 20 0
					&tlmm 21 0
					&tlmm 22 0
					/* Display gpio pins */
					&tlmm 12 0
					&tlmm 113 0
					/* Test gpio pins */
					&tlmm 24 0>;
		};
	};

	tlmm-vm-test {
		compatible = "qcom,tlmm-vm-test";
		qcom,master;
		tlmm-vm-gpio-list = <&tlmm 24 0>; // Use a pin that is not utilized by PVM
	};

	qti,smmu-proxy {
		compatible = "smmu-proxy-sender";
	};

	qcom,seccamtest {
		compatible = "qcom,seccamtest";
		qti,smmu-proxy-cb-id = <QTI_SMMU_PROXY_CAMERA_CB>;
	};

};

#include "chora-pinctrl.dtsi"
#include "chora-coresight.dtsi"
#include "chora-debug.dtsi"
#include "chora-qupv3.dtsi"
#include "chora-usb.dtsi"
#include "chora-thermal.dtsi"
#include "chora-walt.dtsi"
#include "chora-regulators.dtsi"
#include "ipcc-test-chora.dtsi"
/delete-node/ &ipcc_self_ping_mpss;
/delete-node/ &ipcc_self_ping_adsp;
/delete-node/ &ipcc_self_ping_wpss;
#include "msm-rdbg-monaco.dtsi"

&qupv3_se5_2uart {
	status = "ok";
};
